# pse84_a0 register map
Vendor: Infineon Technologies; Series: PSE84_A0; File version: 1.0
CPU: CM33 r0p1, little endian, MPU, FPU, VTOR, 3 interrupt priority bits
Registers are 32-bit, read-write, reset 0x0 unless marked. A register's access mark holds for its fields unless they carry their own. Offsets are from the block's base; [hi:lo] are bit positions; lines under a group give offsets from that group; {n}, {i} and the like mark numbered series; 'fields as' and 'values as' point back to an identical list; <NAME> marks a mode.

## SRSS (part 2 of 2) — SRSS Core Registers
Base 0x42400000
0x1540 CSV_PILO_REF_SEL — Select CSV Reference clock for PILO clock
  [1:0] PILO_REF_MUX — Selects a source for clock clk_ref_pilo. Note that not all products support all clock sources. Selecting a clock source that is not supported will result in undefined behavior. It takes four cycles of the originally selected clock to switch away from it. Do not disable the original clock during this time. PILO is a source for clk_lf. Do not select LF when LF clock is using PILO.
    0=LFCLK (Root of the low-speed clock tree (LFCLK)); 1=ILO (Internal Low frequency Oscillator, available in Active, DeepSleep, and Hibernate. (Product Specific)); 2=WCO (Watch-crystal oscillator input, available in Active, DeepSleep, and Hibernate. (Product Specific)); 3=TIMERCLK (Timer clock. Divided clock from IHO set to 1MHz. Available only during Active mode. If this clock is selected as reference, CSV will be disabled by hardware when entering lower power modes (DPSLP) and re-enabled back in Active.)
{0x1600+0x20*i} CLK_DPLL_LP[{i}] (i=0..1) group — DPLL LP Configuration Register
  0x00 CONFIG reset 0x20116 — DPLL_LP Configuration Register
    [31] ENABLE — Master enable for PLL. Setup FEEDBACK_DIV, REFERENCE_DIV, and OUTPUT_DIV at least one cycle before setting ENABLE=1. fOUT = (FEEDBACK_DIV + FRAC_EN*FRAC_DIV/2^24) * (fREF / REFERENCE_DIV) / (OUTPUT_DIV) 0: Block is disabled. When the PLL disables, hardware controls the bypass mux as described in BYPASS_SEL, before disabling the PLL circuit. 1: Block is enabled
    [29:28] BYPASS_SEL — Bypass mux located just after PLL output. This selection is glitch-free and can be changed while the PLL is running. When changing BYPASS_SEL, do not turn off the reference clock or PLL clock for five cycles (whichever is slower).
      0=AUTO (Automatic using lock indicator. When unlocked, automatically selects PLL reference input (bypass mode). When locked, automatically selects PLL output. If ENABLE=0, automatically selects PLL reference input.); 1=LOCKED_OR_NOTHING (Similar to AUTO, except the clock is gated off when unlocked. This is compatible with clock supervision, because the supervisors allow no clock during startup (until a timeout occurs), and the clock targets the proper frequency whenever it is running. If ENABLE=0, no clock is output.); 2=PLL_BYPASS (Select PLL reference input (bypass mode). Ignores lock indicator); 3=PLL_OUT (Select PLL output. Ignores lock indicator. If ENABLE=0, no clock is output.)
    [27] PLL_DCO_MODE — dco_mode='0' DCO freq 160-310MHz , '1' - DCO freq 310-480MHz
    [20:16] OUTPUT_DIV — Control bits for Output divider. Set the divide value before enabling the PLL, and do not change it while PLL is enabled. 0: illegal (undefined behavior) 1: divide by 1. Suitable for direct usage as HFCLK source. 2: divide by 2. Suitable for direct usage as HFCLK source. ... 16: divide by 16. Suitable for direct usage as HFCLK source. >16: illegal (undefined behavior)
    [12:8] REFERENCE_DIV — Control bits for reference divider. Set the divide value before enabling the PLL, and do not change it while PLL is enabled. 0: illegal (undefined behavior) 1: divide by 1 ... 16: divide by 16 others: illegal (undefined behavior) When using fractional mode, the jitter specs are met over the restricted range of 1 to 4, inclusive.
    [7:0] FEEDBACK_DIV — Control bits for feedback divider. Set the divide value before enabling the PLL, and do not change it while PLL is enabled. 0-15: illegal (undefined behavior) 16: divide by 16 ... 200: divide by 200 >200: illegal (undefined behavior) When using fractional mode, the jitter specs are met over the restricted range of 27 to 47, inclusive.
  0x04 CONFIG2 — DPLL_LP Configuration Register 2
    [31] FRAC_EN — Enables fractional division mode. When using fractional division mode, see CLK_PLL400M_CONFIG.LOCK_DELAY for an additional configuration requirement.
    [30:28] FRAC_DITHER_EN
    [23:0] FRAC_DIV — Control bits for fractional divider. This value is interpreted as a fraction of the PFD frequency, i.e. fPFD * (FRAC_DIV/2^24). This field can be dynamically updated within the 1000ppm control limit. It takes up to 115 AHB cycles to transfer the setting to the PLL, and writes that occur faster may be silently ignored and require the application to write again after the previous update has finished. Reading the register returns the accepted value. The PLL will start targeting the new value, but it may take significant time (milliseconds) to stabilize at the new average value. Do not change the FRAC_DIV setting while the PLL is initially locking.
  0x08 CONFIG3 — DPLL_LP Configuration Register 3
    [31] SSCG_EN — Enables spreading mode. When using spreading, see CLK_PLL400M_CONFIG.LOCK_DELAY for an additional configuration requirement.
    [28] SSCG_MODE
    [24] SSCG_DITHER_EN
    [18:16] SSCG_RATE
    [9:0] SSCG_DEPTH
  0x0C CONFIG4 reset 0xF — DPLL_LP Configuration Register 4
    [31] DCO_SD_EN — Enable the DCO sigma-delta modulator to reduce sideband frequency spurs caused by periodicity of DCO_CODE LSB changes. Note that enabling this introduces additional jitter which may exceed the timing closure limits near the maximum frequency. 0: disable sigma-delta modulator. 1: enable sigma-delta modulator. User must ensure the frequency remains with timing closure (consult Cypress).
    [13] PLL_CS_PB2_DIS — disable internal bias
    [10:0] DCO_CODE — Initial DCO code. It is recommended to leave this at the default setting.
  0x10 CONFIG5 reset 0x709870BA — DPLL_LP Configuration Register 5
    [31:28] KP_SSCG — Gain of P/I loop filter proportional path for SSCG operation. Gain coefficient is 2^KP, eg. 0=>1, 15=>32768.
    [23:20] KP_FRACT — Gain of P/I loop filter proportional path for FRACT operation. Gain coefficient is 2^KP, eg. 0=>1, 15=>32768.
    [19:16] KP_INT — Gain of P/I loop filter integrator path for INT operation. Gain coefficient is 2^KP, eg. 0=>1, 15=>32768.
    [15:12] KI_SSCG — Gain of P/I loop filter proportional path for SSCG operation. Gain coefficient is 2^KI, eg. 0=>1, 15=>32768.
    [7:4] KI_FRACT — Gain of P/I loop filter proportional path for FRACT operation. Gain coefficient is 2^KI, eg. 0=>1, 15=>32768.
    [3:0] KI_INT — Gain of P/I loop filter integrator path for INT operation. Gain coefficient is 2^KI, eg. 0=>1, 15=>32768.
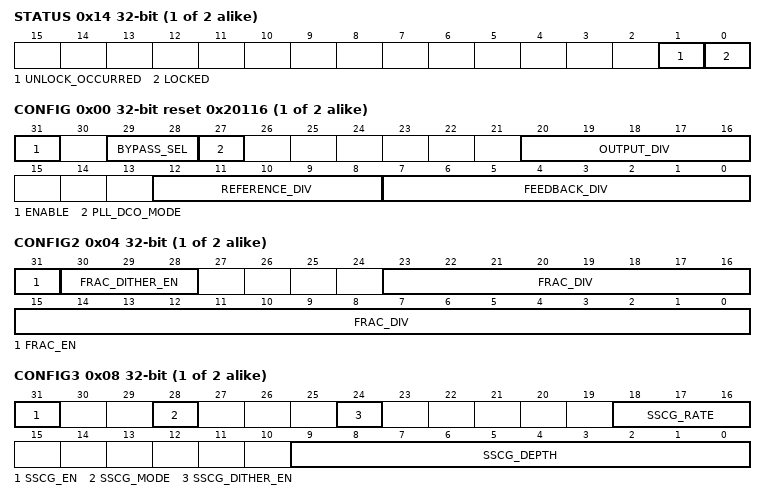
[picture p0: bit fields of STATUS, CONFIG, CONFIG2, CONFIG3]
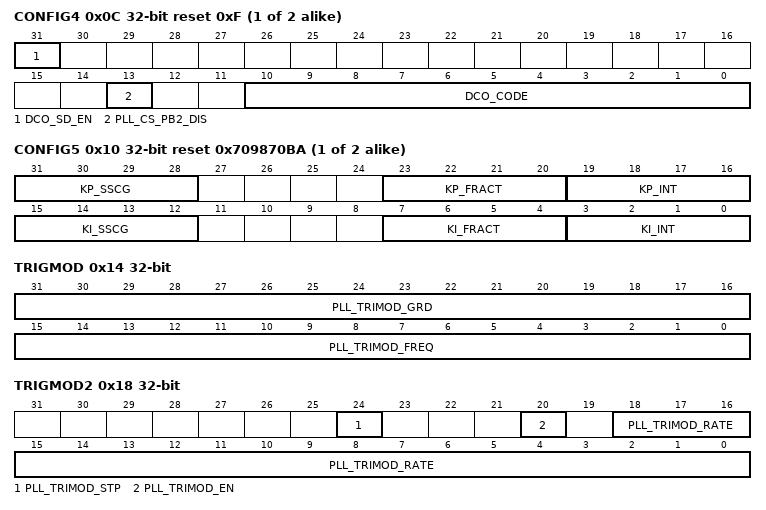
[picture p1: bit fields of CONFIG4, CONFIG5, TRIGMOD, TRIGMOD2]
  0x14 STATUS — DPLL_LP Status Register
    [1] UNLOCK_OCCURRED — This bit sets whenever the PLL Lock bit goes low, and stays set until cleared by firmware.
    [0] LOCKED ro — PLL Lock Indicator
0x1800 CLK_DPLL_HP group — DPLL HP Configuration Register
  0x00 CONFIG reset 0x1013 — DPLL_HP Configuration Register
    [31] ENABLE — Master enable for PLL. Setup PLL for integer, fract or SCSG at least one cycle before setting ENABLE=1. 0: Block is disabled. When the PLL disables, hardware controls the bypass mux as described in BYPASS_SEL, before disabling the PLL circuit. 1: Block is enabled
    [29:28] BYPASS_SEL — Bypass mux located just after PLL output. This selection is glitch-free and can be changed while the PLL is running. When changing BYPASS_SEL, do not turn off the reference clock or PLL clock for five cycles (whichever is slower).
      values as CLK_DPLL_LP[0].CONFIG.BYPASS_SEL
    [14:12] PLL_FREQ_KDIV_SEL — K-divider division factor (K = kdiv_sel_i + 1 )
    [10:8] PLL_FREQ_PDIV_SEL — P-divider division factor (P = pdiv_sel_i + 1 ) (Cannot be changed on the fly when the PLL is enabled)
    [7:0] PLL_FREQ_NDIV_INT_SEL — N-divider division factor (N = ndiv_sel_i + 1 ) (Cannot be changed on the fly when the PLL is enabled)
  0x04 CONFIG2 reset 0x8E00000 — DPLL_HP Configuration Register 2
    [27:24] PLL_IVR_TRIM — control word for trimming the regulated voltage that is internally generated from the 1v8 supply (default value = '10') (Cannot be changed on the fly when the PLL is enabled)
    [23:21] PLL_FREQ_MODE_SEL — selects the waiting time for Power Initialization sequence, based on the PLL running frequency (Cannot be changed on the fly when the PLL is enabled)
    [20:0] PLL_FREQ_NDIV_FRACT_SEL — N-divider division factor (N = ndiv_sel_i + 1) (Cannot be changed on the fly when the PLL is enabled)
  0x08 CONFIG3 reset 0x1 — DPLL_HP Configuration Register 3
    [29] PLL_FDSM_SEL — DSM clock division select (Cannot be changed on the fly when the PLL is enabled)
      0=DIV_BY_4 (Divide output by 4); 1=DIV_BY_2 (Divide output by 2)
    [0] PLL_CLKR_SEL — Select retimed reference clock (Cannot be changed on the fly when the PLL is enabled)
  0x0C CONFIG4 reset 0x27618AC — DPLL_HP Configuration Register 4
    [30:27] PLL_FLOCK_OBSWIN — Period over which PQDIFF is computed/observed. If 0 = use HW computed window. Supported values: 0-4 and 8 (Cannot be changed on the fly when the PLL is enabled)
    [26:23] PLL_FLOCK_LK_WAITPER — Period over which flock_en_thresh must be met in order for Freq Locking. Supported values: 0-8 (Cannot be changed on the fly when the PLL is enabled)
    [22:20] PLL_FLOCK_LK_THRESH — PQDIFF threshold under which DLL asserts Freq LOCK (Cannot be changed on the fly when the PLL is enabled)
    [19:16] PLL_FLOCK_WAITPER — Period over which flock_en_thresh must be met in order for FINE Filtering enabling. Supported values: 0-8 (Cannot be changed on the fly when the PLL is enabled)
    [13:11] PLL_FLOCK_EN_THRESH — PQDIFF threshold under which FINE Filtering gets enabled (Cannot be changed on the fly when the PLL is enabled) CONFIG.PLL_FREQ_NDIV_INT_SEL >= 20 -> PLL_FLOCK_EN_THRESH == 0x7; CONFIG.PLL_FREQ_NDIV_INT_SEL < 20 -> PLL_FLOCK_EN_THRESH == 0x3;
    [9:5] PLL_LF_LC_BETA — Beta value of the coarse filter (Cannot be changed on the fly when the PLL is enabled)
    [4:0] PLL_LF_LC_ALPHA — Alpha value of the coarse filter (Cannot be changed on the fly when the PLL is enabled)
  0x10 CONFIG5 reset 0x1294 — DPLL_HP Configuration Register 5
    [28:16] PLL_DT_CAL_DIG ro — FW should read pll_dutycal_dig_o only when pll_dutycal_ok is high to know the status of DUTY CAL circuit.
    [12] PLL_LF_SET_PARAMS — enable for external loop filter control (alpha and beta values) (Cannot be changed on the fly when the PLL is enabled)
    [9:5] PLL_LF_BETA — External beta value (Cannot be changed on the fly when the PLL is enabled) Fref/(pdiv_sel_i+1) >= 25MHz -> PLL_LF_BETA == 0x14 Fref/(pdiv_sel_i+1) < 25MHz -> PLL_LF_BETA == 0x10
    [4:0] PLL_LF_ALPHA — External alpha value (Cannot be changed on the fly when the PLL is enabled)
  0x14 TRIGMOD — DPLL_HP Trigmod SSCG Register
    [31:16] PLL_TRIMOD_GRD — Triangular-Frequency Modulation: modulation gradient. See formula in the BROS (word file) (Can be changed when PLL is enabled but cannot be changed on the fly when pll_trimod_en_i=1)
    [15:0] PLL_TRIMOD_FREQ — Triangular-Frequency Modulation: modulation frequency. See formula in the BROS (word file) (Can be changed when PLL is enabled but cannot be changed on the fly when pll_trimod_en_i=1)
  0x18 TRIGMOD2 — DPLL_HP Trigmod2 SSCG Register
    [24] PLL_TRIMOD_STP — Triangular-Frequency Modulation stop
    [20] PLL_TRIMOD_EN — Triangular-Frequency Modulation enable
    [18:0] PLL_TRIMOD_RATE — triangular frequency modulation: trimod_rate = mod_grad_i * 16/mod_freq_i (Cannot be changed on the fly when the PLL is enabled)
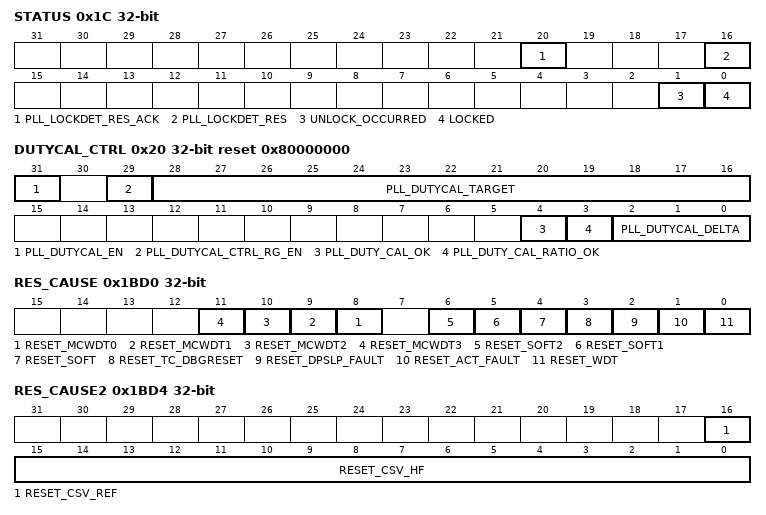
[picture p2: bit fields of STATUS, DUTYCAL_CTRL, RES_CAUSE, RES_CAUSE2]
  0x1C STATUS — DPLL_HP Status Register
    [20] PLL_LOCKDET_RES_ACK ro — acknowledgement for lock detection restart
    [16] PLL_LOCKDET_RES — Restart lock detector
    [1] UNLOCK_OCCURRED — This bit sets whenever the PLL Lock bit goes low, and stays set until cleared by firmware.
    [0] LOCKED ro — PLL Lock Indicator
  0x20 DUTYCAL_CTRL reset 0x80000000 — DPLL_HP_User DUTYCAL Control Register
    [31] PLL_DUTYCAL_EN — dutycal: enables duty cycle calibration (Cannot be changed on the fly when the PLL is enabled)
    [29] PLL_DUTYCAL_CTRL_RG_EN — dutycal: enables ring oscillator for duty cycle digitization (Cannot be changed on the fly when the PLL is enabled)
    [28:16] PLL_DUTYCAL_TARGET — duty cycle target (Cannot be changed on the fly when the PLL is enabled)
    [4] PLL_DUTY_CAL_OK ro — Status of the duty calibration ok
    [3] PLL_DUTY_CAL_RATIO_OK ro — Status of the duty calibration ratio ok
    [2:0] PLL_DUTYCAL_DELTA — dutycal: margins for the duty cycle calibration error (Cannot be changed on the fly when the PLL is enabled)
0x1BD0 RES_CAUSE — Reset Cause Observation Register
  [n+8] RESET_MCWDT{n} (n=0..3) — Multi-Counter Watchdog timer reset #{n}. This is a low-voltage cause bit that hardware clears when the low-voltage supply is initialized (see comments above).
  [6] RESET_SOFT2 — CPU[2] requested a system reset through it's SYSRESETREQ. This can be done via a debugger probe or in firmware. This is a low-voltage cause bit that hardware clears when the low-voltage supply is initialized (see comments above).
  [5] RESET_SOFT1 — CPU[1] requested a system reset through it's SYSRESETREQ. This can be done via a debugger probe or in firmware. This is a low-voltage cause bit that hardware clears when the low-voltage supply is initialized (see comments above).
  [4] RESET_SOFT — CPU[0] requested a system reset through it's SYSRESETREQ. This can be done via a debugger probe or in firmware. This is a low-voltage cause bit that hardware clears when the low-voltage supply is initialized (see comments above).
  [3] RESET_TC_DBGRESET — Test controller or debugger asserted reset. This asserts low-voltage resets including the debug domain. This is a low-voltage cause bit that hardware clears when the low-voltage supply is initialized (see comments above).
  [2] RESET_DPSLP_FAULT
  [1] RESET_ACT_FAULT — Fault logging system requested a reset from its Active logic. This is a low-voltage cause bit that hardware clears when the low-voltage supply is initialized (see comments above).
  [0] RESET_WDT — A basic WatchDog Timer (WDT) reset has occurred since last power cycle. ULP products: This is a low-voltage cause bit that hardware clears when the low-voltage supply is initialized (see comments above). For products that support high-voltage cause detection, this bit blocks recording of other high-voltage cause bits, except RESET_PORVDDD, or *XRES. Hardware clears this bit during POR. This bit is not blocked by other HV cause bits.
0x1BD4 RES_CAUSE2 — Reset Cause Observation Register 2
  [16] RESET_CSV_REF — Clock supervision logic requested a reset due to loss or frequency violation of the reference clock source that is used to monitor the other HF clock sources.
  [15:0] RESET_CSV_HF — Clock supervision logic requested a reset due to loss or frequency violation of a high-frequency clock. Each bit index K corresponds to a HFCLK<K>. Unimplemented clock bits return zero.
0x1BE4 RES_PXRES_CTL wo — Programmable XRES Control Register
  [0] PXRES_TRIGGER — Triggers PXRES. This causes a full-scope reset and reboot.
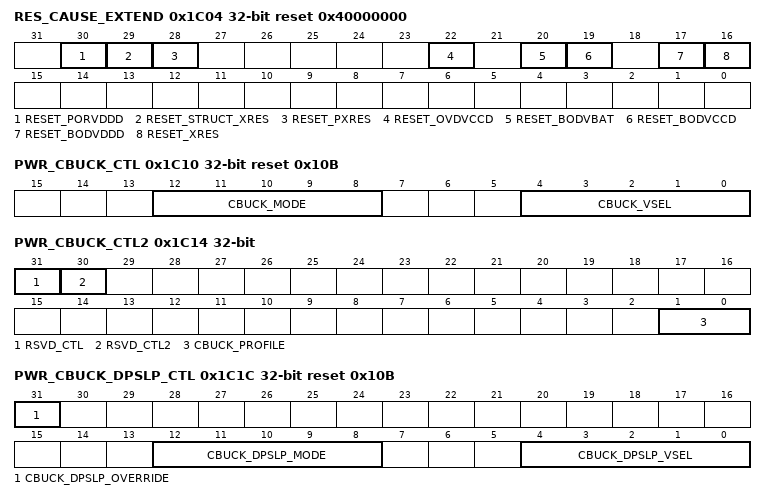
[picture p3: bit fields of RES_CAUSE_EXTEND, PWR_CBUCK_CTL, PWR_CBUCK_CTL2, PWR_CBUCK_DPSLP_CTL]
0x1C04 RES_CAUSE_EXTEND reset 0x40000000 — Extended Reset Cause Observation Register
  [30] RESET_PORVDDD — Indicator that a POR occurred. This is a high-voltage cause bit, and hardware clears the other bits when this one is set. It does not block further recording of other high-voltage causes.
  [29] RESET_STRUCT_XRES — Structural reset was asserted. This is a high-voltage cause bit that blocks recording of other high-voltage cause bits, except RESET_PORVDDD, *XRES, or WDT. Hardware clears this bit during POR. This bit is not blocked by other HV cause bits.
  [28] RESET_PXRES — PXRES triggered. This is a high-voltage cause bit that blocks recording of other high-voltage cause bits, except RESET_PORVDDD, *XRES, or WDT. Hardware clears this bit during POR. This bit is not blocked by other HV cause bits.
  [22] RESET_OVDVCCD — Overvoltage detection on the internal core VCCD supply. This is a high-voltage cause bit that blocks recording of other high-voltage cause bits, except RESET_PORVDDD, *XRES, or WDT. Hardware clears this bit during POR.
  [20] RESET_BODVBAT — External VBAT supply crossed brown-out limit. Note that this cause will only be observable as long as the VDDD supply does not go below the POR (power on reset) detection limit. Below this limit it is not possible to reliably retain information in the device. This is a high-voltage cause bit that blocks recording of other high-voltage cause bits, except RESET_PORVDDD, *XRES, or WDT. Hardware clears this bit during POR.
  [19] RESET_BODVCCD — Internal VCCD core supply crossed the brown-out limit. Note that this detector will detect gross issues with the internal core supply, but may not catch all brown-out conditions. Functional and timing supervision (CSV, WDT) is provided to create fully failsafe internal crash detection. This is a high-voltage cause bit that blocks recording of other high-voltage cause bits, except RESET_PORVDDD, *XRES, or WDT. Hardware clears this bit during POR.
  [17] RESET_BODVDDD — External VDDD supply crossed brown-out limit. Note that this cause will only be observable as long as the VDDD supply does not go below the POR (power on reset) detection limit. Below this limit it is not possible to reliably retain information in the device. This is a high-voltage cause bit that blocks recording of other high-voltage cause bits, except RESET_PORVDDD, *XRES, or WDT. Hardware clears this bit during POR.
  [16] RESET_XRES — External XRES pin was asserted. This is a high-voltage cause bit that blocks recording of other high-voltage cause bits, except RESET_PORVDDD, or WDT. Hardware clears this bit during POR. This bit is not blocked by other HV cause bits.
0x1C10 PWR_CBUCK_CTL reset 0x10B — Core Buck Control Register
  [12:8] CBUCK_MODE — CBUCK mode. Low ripple (high power) modes are intended for analog that needs low ripple. Low power mode is suitable for digital processing. The CBUCK mode is defined as = {mode*_sr_mode, mode*_sr_hp_submode[1:0], mode*_sr_lp_submode[1:0]} The actual CBUCK mode is the maximum of this setting and the settings of all enabled step-down regulators. 0x11: HP,Hysteretic PFM, High-Low (default Active) 0x01: LP,Hysteretic PFM, High-Low (default DeepSleep)
  [4:0] CBUCK_VSEL — Voltage output selection. This register is only reset by XRES, HIBERNATE wakeup, or supply supervision reset. The actual CBUCK voltage is the maximum of this setting and the settings for selected mode (see PWR_BUCK_CTL.MODE). These settings follow the formula (0.58+0.02*CBUCK_VSEL). 0: 0.58V, 1: 0.60V, 2: 0.62V, 3: 0.64V, 4: 0.66V, 5: 0.68V, 6: 0.70V, 7: 0.72V, 8: 0.74V, 9: 0.76V, 10: 0.78V, 11: 0.80V, 12: 0.82V, 13: 0.84V, 14: 0.86V, 15: 0.88V, 16: 0.90V, 17: 0.92V, 18: 0.94V, 19: 0.96V, 20: 0.98V, 21: 1.00V, 22: 1.02V, 23: 1.04V, 24: 1.06V, 25: 1.08V, 26: 1.10V, 27: 1.12V, 28: 1.14V, 29: 1.16V, 30: 1.18V, 31: 1.20V.
0x1C14 PWR_CBUCK_CTL2 — Core Buck Control Register 2
  [31] RSVD_CTL
  [30] RSVD_CTL2
  [1:0] CBUCK_PROFILE — Selects between CBUCK mode profiles. When CBUCK_USE_SETTING=1, PWR_CBUCK_CTL settings are included in the harmonization and the maximum of the respective mode is used. 00: Mode0: VSEL=0.8V; MODE= HP,Hysteretic PFM, High-Low (17) 01: Mode1: VSEL=0.7V; MODE=17 10: Mode2: VSEL=0.9V; MODE=17 11: Forces the CBUCK to use the settings in PWR_CBUCK_CTL register, ignoring the other hardware requests. This can be used as part of a firmware algorithm to change the voltage of an regulator. This bit is cleared by any reset].
0x1C1C PWR_CBUCK_DPSLP_CTL reset 0x10B — Core Buck Deepsleep Control Register
  [31] CBUCK_DPSLP_OVERRIDE — Causes the settings in CBUCK_DPSLP_VSEL and CBUCK_DPSLP_MODE in this register to be used during DEEPSLEEP. Can be used to override the normal hardware voltage behavior of 0.7V and LP, LP,Hysteretic PFM, High-Low (default DeepSleep)
  [12:8] CBUCK_DPSLP_MODE — CBUCK mode. Low ripple (high power) modes are intended for analog that needs low ripple. Low power mode is suitable for digital processing. The CBUCK mode is defined as = {mode*_sr_mode, mode*_sr_hp_submode[1:0], mode*_sr_lp_submode[1:0]} CBUCK_DPSLP_OVERRIDE=1 will casue these settings to be used during DEEPSLEEP mode. 0x11: HP,Hysteretic PFM, High-Low (default Active) 0x01: LP,Hysteretic PFM, High-Low (default DeepSleep)
  [4:0] CBUCK_DPSLP_VSEL — Voltage output selection for DEEPSLEEP. CBUCK_DPSLP_OVERRIDE=1 will casue these settings to be used during DEEPSLEEP mode. This register is only reset by XRES, HIBERNATE wakeup, or supply supervision reset. These settings follow the formula (0.58+0.02*CBUCK_VSEL). 0: 0.58V, 1: 0.60V, 2: 0.62V, 3: 0.64V, 4: 0.66V, 5: 0.68V, 6: 0.70V, 7: 0.72V, 8: 0.74V, 9: 0.76V, 10: 0.78V, 11: 0.80V, 12: 0.82V, 13: 0.84V, 14: 0.86V, 15: 0.88V, 16: 0.90V, 17: 0.92V, 18: 0.94V, 19: 0.96V, 20: 0.98V, 21: 1.00V, 22: 1.02V, 23: 1.04V, 24: 1.06V, 25: 1.08V, 26: 1.10V, 27: 1.12V, 28: 1.14V, 29: 1.16V, 30: 1.18V, 31: 1.20V.
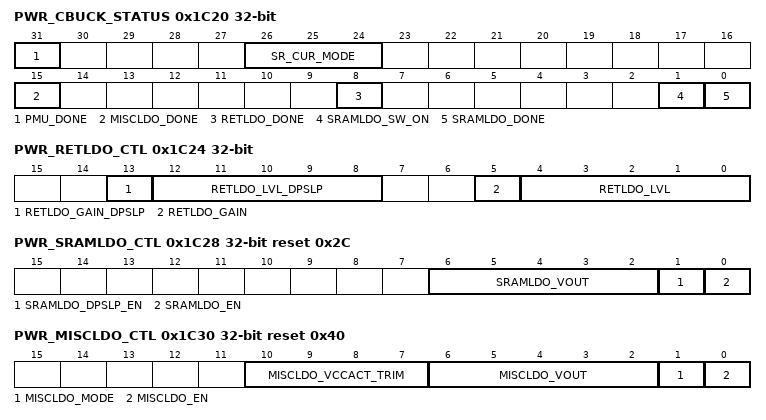
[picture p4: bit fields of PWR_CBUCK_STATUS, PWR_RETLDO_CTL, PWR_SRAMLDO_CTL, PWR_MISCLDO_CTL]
0x1C20 PWR_CBUCK_STATUS ro — Core Buck Status Register
  [31] PMU_DONE — Indicates the power management unit is finished with a transition. 0: PMU busy 1: PMU done
  [26:24] SR_CUR_MODE — Indicates the switching regulator current operating mode
  [15] MISCLDO_DONE — Indicates the MISCLDO is finished with a transition. 0: MISCLDO busy 1: MISCLDO done
  [8] RETLDO_DONE — Indicates the RETLDO is finished with a transition. 0: RETLDO busy 1: RETLDO done
  [1] SRAMLDO_SW_ON — Indicates the state of the SRAMLDO bypass switch 0: SRAMLDO enabled 1: SRAMLDO bypassed
  [0] SRAMLDO_DONE — Indicates the SRAMLDO is finished with a transition. 0: SRAMLDO busy 1: SRAMLDO done
0x1C24 PWR_RETLDO_CTL — RETLDO Control Register
  [13] RETLDO_GAIN_DPSLP — RETLDO Gain during Deepslp modes 0: 2.00 1: 2.47
  [12:8] RETLDO_LVL_DPSLP — RETLDO output voltage during DEEPSLEEP modes retldo_gain=0 retldo_gain=1 retref_lvl Temp Temp 25C-125C Temp Temp 25C-125C <4:0> -40C -40C 00000 0.6150 0.550 0.7595 0.679 00001 0.6262 0.560 0.7733 0.691 00010 0.6374 0.570 0.7871 0.704 00011 0.6485 0.580 0.8010 0.716 00100 0.6597 0.590 0.8148 0.728 00101 0.6709 0.600 0.8286 0.741 00110 0.6821 0.610 0.8424 0.753 00111 0.6933 0.620 0.8562 0.765 01000 0.7045 0.630 0.8700 0.778 01001 0.7045 0.630 0.8700 0.778 01010 0.7045 0.630 0.8700 0.778 01011 0.7045 0.630 0.8700 0.778 01100 0.7045 0.630 0.8700 0.778 01101 0.7045 0.630 0.8700 0.778 01110 0.7045 0.630 0.8700 0.778 01111 0.7045 0.630 0.8700 0.778 10000 0.4361 0.390 0.5386 0.481 10001 0.4473 0.400 0.5524 0.494 10010 0.4585 0.410 0.5662 0.506 10011 0.4696 0.420 0.5800 0.519 10100 0.4808 0.430 0.5938 0.531 10101 0.4920 0.440 0.6076 0.543 10110 0.5032 0.450 0.6214 0.556 10111 0.5144 0.460 0.6352 0.568 11000 0.5255 0.470 0.6490 0.580 11001 0.5367 0.480 0.6629 0.593 11010 0.5479 0.490 0.6767 0.605 11011 0.5591 0.500 0.6905 0.617 11100 0.5703 0.510 0.7043 0.630 11101 0.5815 0.520 0.7181 0.642 11110 0.5926 0.530 0.7319 0.654 11111 0.6038 0.540 0.7457 0.667
  [5] RETLDO_GAIN — RETLDO Gain During Active mode 0: 2.00 1: 2.47
  [4:0] RETLDO_LVL — RETLDO output voltage during DEEPSLEEP modes retldo_gain=0 retldo_gain=1 retref_lvl Temp Temp 25C-125C Temp Temp 25C-125C <4:0> -40C -40C 00000 0.6150 0.550 0.7595 0.679 00001 0.6262 0.560 0.7733 0.691 00010 0.6374 0.570 0.7871 0.704 00011 0.6485 0.580 0.8010 0.716 00100 0.6597 0.590 0.8148 0.728 00101 0.6709 0.600 0.8286 0.741 00110 0.6821 0.610 0.8424 0.753 00111 0.6933 0.620 0.8562 0.765 01000 0.7045 0.630 0.8700 0.778 01001 0.7045 0.630 0.8700 0.778 01010 0.7045 0.630 0.8700 0.778 01011 0.7045 0.630 0.8700 0.778 01100 0.7045 0.630 0.8700 0.778 01101 0.7045 0.630 0.8700 0.778 01110 0.7045 0.630 0.8700 0.778 01111 0.7045 0.630 0.8700 0.778 10000 0.4361 0.390 0.5386 0.481 10001 0.4473 0.400 0.5524 0.494 10010 0.4585 0.410 0.5662 0.506 10011 0.4696 0.420 0.5800 0.519 10100 0.4808 0.430 0.5938 0.531 10101 0.4920 0.440 0.6076 0.543 10110 0.5032 0.450 0.6214 0.556 10111 0.5144 0.460 0.6352 0.568 11000 0.5255 0.470 0.6490 0.580 11001 0.5367 0.480 0.6629 0.593 11010 0.5479 0.490 0.6767 0.605 11011 0.5591 0.500 0.6905 0.617 11100 0.5703 0.510 0.7043 0.630 11101 0.5815 0.520 0.7181 0.642 11110 0.5926 0.530 0.7319 0.654 11111 0.6038 0.540 0.7457 0.667
0x1C28 PWR_SRAMLDO_CTL reset 0x2C — SRAMLDO Control Register
  [6:2] SRAMLDO_VOUT — SRAMLDO output voltage Setting Voltage(V) Setting Voltage(V) 00000 0.58 10000 0.90 00001 0.60 10001 0.92 00001 0.60 10001 0.92 00010 0.62 10010 0.94 00011 0.64 10011 0.96 00100 0.66 10100 0.98 00101 0.68 10101 1.00 00110 0.70 10110 1.02 00111 0.72 10111 1.04 01000 0.74 11000 1.06 01001 0.76 11001 1.08 01010 0.78 11010 1.10 01011 0.80 11011 1.12 01100 0.82 11100 1.14 01101 0.84 11101 1.16 01110 0.86 11110 1.18 01111 0.88 11111 1.20
  [1] SRAMLDO_DPSLP_EN — Enable SRAMLDO during deepsleep modes for fast wakeup time versus power savings.
  [0] SRAMLDO_EN — SRAM LDO enable 0: Disabled (switch VCCD->VCCSRAM enabled) 1: Enabled (switch VCCD->VCCSRAM disabled)
0x1C30 PWR_MISCLDO_CTL reset 0x40 — MISCLDO Control Register
  [10:7] MISCLDO_VCCACT_TRIM — MISCLDO VCCACT_MISC trim adjustment. Proportional to VCCACT_MISC, numbers below at 0.9V. Setting Adj @0.9V 0111 35mV 0110 30mV 0101 25mV 0100 20mV 0011 15mV 0010 10mV 0001 5mV 0000 0mV 1111 -5mV 1110 -10mV 1110 -10mV 1101 -15mV 1100 -20mV 1011 -25mV 1010 -30mV 1001 -35mV 1000 -40mV
  [6:2] MISCLDO_VOUT — MISCLDO output voltage Setting Voltage(V) Setting Voltage(V) 00000 0.58 10000 0.90 00001 0.60 10001 0.92 00010 0.62 10010 0.94 00011 0.64 10011 0.96 00100 0.66 10100 0.98 00101 0.68 10101 1.00 00110 0.70 10110 1.02 00111 0.72 10111 1.04 01000 0.74 11000 1.06 01001 0.76 11001 1.08 01010 0.78 11010 1.10 01011 0.80 11011 1.12 01100 0.82 11100 1.14 01101 0.84 11101 1.16 01110 0.86 11110 1.18 01111 0.88 11111 1.20
  [1] MISCLDO_MODE — MISCLDO voltage mode 0: MISCLDO output follows VCCACT_MISC 1: MISCLDO output follows miscldo_vout<4:0>
  [0] MISCLDO_EN — MISCLDO enable
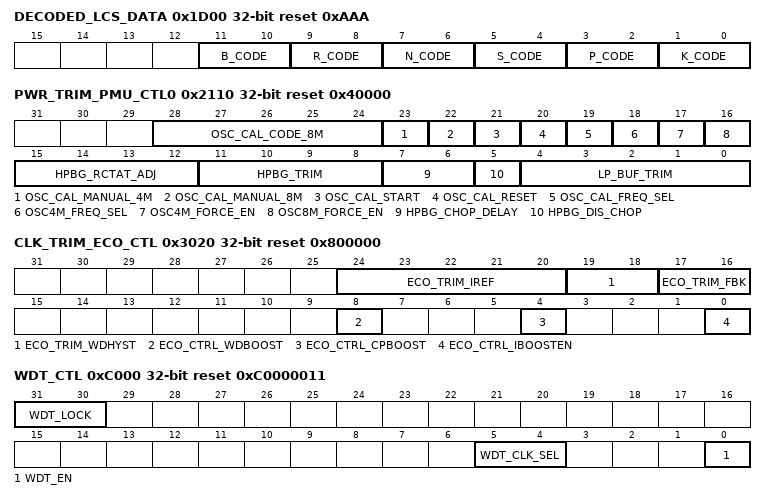
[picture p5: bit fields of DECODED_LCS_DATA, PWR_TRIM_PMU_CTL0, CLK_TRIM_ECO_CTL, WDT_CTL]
0x1D00 DECODED_LCS_DATA ro reset 0xAAA — Decoded Life Cycle Stage Data Register
  [11:10] B_CODE — Indicates status of LCS 'B' bit. 00=Unprogrammed, 11=Valid, 10/01=Invalid
  [9:8] R_CODE — Indicates status of LCS 'R' bit. 00=Unprogrammed, 11=Valid, 10/01=Invalid
  [7:6] N_CODE — Indicates status of LCS 'N' bit*. 00=Unprogrammed, 11=Valid, 10/01=Invalid. Will be '00' if R_CODE is set in RMA LCS
  [5:4] S_CODE — Indicates status of LCS 'S' bit*. 00=Unprogrammed, 11=Valid, 10/01=Invalid. Will be '11' if R_CODE is set in RMA LCS
  [3:2] P_CODE — Indicates status of LCS 'P' bit*. 00=Unprogrammed, 11=Valid, 10/01=Invalid. Will be '11' if R_CODE is set in RMA LCS
  [1:0] K_CODE — Indicates status of LCS 'K' bit. 00=Unprogrammed, 11=Valid, 10/01=Invalid
0x2110 PWR_TRIM_PMU_CTL0 reset 0x40000 — PMU Trim Register 0
  [28:24] OSC_CAL_CODE_8M — Manual trim code to apply to 8MHz oscillator. Only used if osc_cal_manual_8M=1.
  [23] OSC_CAL_MANUAL_4M — Set to use manual cal code for 3.2/4MHz oscillator 0 Use calibration result 1 Use osc_cal_code_4M<4:0>
  [22] OSC_CAL_MANUAL_8M — Set to use manual cal code for 8MHz oscillator 0 Use calibration result 1 Use osc_cal_code_8M<4:0>
  [21] OSC_CAL_START — Start oscillator calibration
  [20] OSC_CAL_RESET — Reset osc cal codes and cal_done signal
  [19] OSC_CAL_FREQ_SEL — Select oscillator to calibrate 0: 8MHz 1: 3.2M/4MHz
  [18] OSC4M_FREQ_SEL — PWM oscillator frequency select 0: 4.0MHz 1 : 3.2MHz
  [17] OSC4M_FORCE_EN — 3.2/4MHz (PWM) oscillator enable - use for Calibration 0: Auto (powerup when used) 1: Enabled (3.2/4MHz always on)
  [16] OSC8M_FORCE_EN — 8MHz oscillator enable - use for Calibration 0: Auto (powerup when used) 1: Enabled (8MHz always on)
  [15:12] HPBG_RCTAT_ADJ — High power bandgap adjust for 0TC (TTTT,50C)
  [11:8] HPBG_TRIM — High power bandgap reference voltage trim Setting VOUT @1.16V VOUT percent 0111 41mV +3.4 percent 0110 35mV +2.9 percent 0101 29mV +2.4 percent 0100 23mV +1.9 percent 0011 18mV +1.5 percent 0010 12mV +1.0 percent 0001 6mV +0.5 percent 0000 0mV 0.0 percent 1111 -5mV -0.4 percent 1110 -11mV -1.0 percent 1101 -16mV -1.4 percent 1100 -22mV -1.9 percent 1011 -27mV -2.4 percent 1010 -32mV -2.8 percent 1001 -38mV -3.4 percent 1000 -43mV -3.9 percent
  [7:6] HPBG_CHOP_DELAY — HPBG chopping delay Setting Delay 00 16us 01 32us 10 64us 11 128us
  [5] HPBG_DIS_CHOP — HPBG disable chop
  [4:0] LP_BUF_TRIM — LP buffer voltage trim, 2's compliment format Setting Vref(V) Setting Vref(V) 00000 0.600 10000 0.520 (-13.3 percent) 00001 0.605 (+0.83 percent) 10001 0.525 (-12.5 percent) 00010 0.610 (+1.67 percent) 10010 0.530 (-11.7 percent) 00011 0.615 (+2.50 percent) 10011 0.535 (-10.8 percent) 00100 0.620 (+3.33 percent) 10100 0.540 (-10.0 percent) 00101 0.625 (+4.17 percent) 10101 0.545 (-9.17 percent) 00110 0.630 (+5.00 percent) 10110 0.550 (-8.33 percent) 00111 0.635 (+5.83 percent) 10111 0.555 (-7.50 percent) 01000 0.640 (+6.67 percent) 11000 0.560 (-6.67 percent) 01001 0.645 (+7.50 percent) 11001 0.565 (-5.83 percent) 01010 0.650 (+8.33 percent) 11010 0.570 (-5.00 percent) 01011 0.655 (+9.17 percent) 11011 0.575 (-4.17 percent) 01100 0.660 (+10.0 percent) 11100 0.580 (-3.33 percent) 01101 0.665 (+10.8 percent) 11101 0.585 (-2.50 percent) 01110 0.670 (+11.7 percent) 11110 0.590 (-1.67 percent) 01111 0.675 (+12.5 percent) 11111 0.595 (-0.83 percent)
0x3020 CLK_TRIM_ECO_CTL reset 0x800000 — ECO Trim Register
  [24:20] ECO_TRIM_IREF — Current bias trim input pin
  [19:18] ECO_TRIM_WDHYST — Watchdog hysteresis trim
  [17:16] ECO_TRIM_FBK — Feedback resistance trim
  [8] ECO_CTRL_WDBOOST — Watchdog trim
  [4] ECO_CTRL_CPBOOST — Amplitude trim
  [0] ECO_CTRL_IBOOSTEN — Current boost enable input pin
0x4000 RAM_TRIM group — SRAM Trim registers
  {0x0+4j} TRIM_RAM_CTL[{j}] (j=0..9) — Trim Register for RAM Type 0
    [31:0] TRIM — Trim value for RAM Type 0
0xC000 WDT_CTL reset 0xC0000011 — Watchdog Counter Control Register (Type A)
  [31:30] WDT_LOCK — Prohibits writing to WDT_*, CLK_ILO_CONFIG, CLK_SELECT.LFCLK_SEL, and CLK_TRIM_ILO_CTL registers when not equal 0. Requires at least two different writes to unlock. A change in WDT_LOCK takes effect beginning with the next write cycle. Note that this field is 2 bits to force multiple writes only. It represents only a single write protect signal protecting all those registers at the same time. WDT will lock on any reset. This field is not retained during DEEPSLEEP or HIBERNATE mode, so the WDT will be locked after wakeup from these modes.
    0=NO_CHG (No effect); 1=CLR0 (Clears bit 0); 2=CLR1 (Clears bit 1); 3=SET01 (Sets both bits 0 and 1)
  [5:4] WDT_CLK_SEL — Select source for WDT. Not all products support all clock sources. Selecting a clock source that is not supported will result in undefined behavior. Writes to this field are ignored unless the WDT is unlock using WDT_LOCK register. It takes four cycles of the originally selected clock to switch away from it. Do not disable the original clock during this time.
    0=ILO (ILO - Internal Low-speed Oscillator, if present. With this option selected, ILO reset is suppressed in Hibernate mode.); 1=PILO (PILO - Precision ILO. If present. With this option selected, PILO reset is suppressed in Hibernate mode.); 2=RTC (RTC - Selected clk_rtc source, if present. This choice is not recommended for applications that rely upon the watchdog timer for safety or security, unless the product supports clock supervision of clk_rtc (CSV_RTC). Generation of clk_rtc is not protected by WDT_LOCK and is in a different memory region with potentially different security attributes.)
  [0] WDT_EN — Enable this watchdog timer. This field is retained during DEEPSLEEP and HIBERNATE modes.
0xC004 WDT_CNT — Watchdog Counter Count Register (Type A)
  [31:0] COUNTER — Current value of WDT Counter. The write feature of this register is for verification purpose, have no synchronization, and can only be applied when the WDT is fully off. When writing, the value is updated immediately in the WDT counter, but it will read back as the old value until this register resynchronizes just after the negedge of selected WDT clock. Writes will be ignored if they occur when the WDT is enabled.
0xC008 WDT_MATCH reset 0x1000 — Watchdog Counter Match Register (Type A)
  [31:0] MATCH — Match value for Watchdog counter. Every time WDT_COUNTER reaches MATCH an interrupt is generated. Two unserviced interrupts will lead to a system reset (i.e. at the third match).
0xC00C WDT_MATCH2 reset 0x1F — Watchdog Counter Match Register 2 (Type A)
  [4:0] IGNORE_BITS_ABOVE — The number of bits to be considered for matching starting from LSb of the register. Bit indices above this setting are NOT checked against MATCH. This value provides control over the time-to-reset of the watchdog (which happens after 3 successive matches). The four LSBs cannot be ignored for matching. Settings <3 behave like a setting of 3. If the setting is higher than the number of bits in the WDT counter, all actual bits in the counter are matched.
{0xD000+0x40*i} MCWDT_STRUCT[{i}] (i=0..1) group — Multi-Counter Watchdog Timer (Type A)
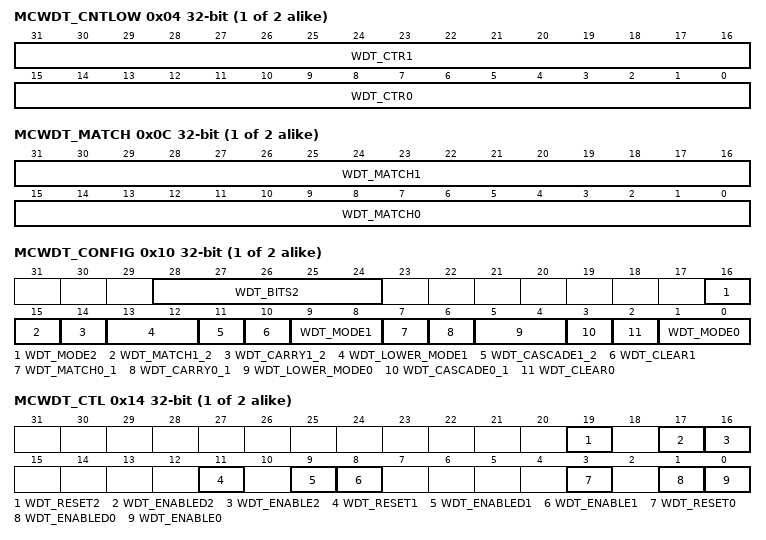
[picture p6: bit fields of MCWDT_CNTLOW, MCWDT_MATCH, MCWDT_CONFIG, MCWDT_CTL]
  0x04 MCWDT_CNTLOW — Multi-Counter Watchdog Sub-counters 0/1
    [31:16] WDT_CTR1 — Current value of sub-counter 1 for this MCWDT. Software writes are ignored when the sub-counter is enabled
    [15:0] WDT_CTR0 — Current value of sub-counter 0 for this MCWDT. Software writes are ignored when the sub-counter is enabled.
  0x08 MCWDT_CNTHIGH — Multi-Counter Watchdog Sub-counter 2
    [31:0] WDT_CTR2 — Current value of sub-counter 2 for this MCWDT. Software writes are ignored when the sub-counter is enabled
  0x0C MCWDT_MATCH — Multi-Counter Watchdog Counter Match Register
    [31:16] WDT_MATCH1 — Match value for sub-counter 1 of this MCWDT
    [15:0] WDT_MATCH0 — Match value for sub-counter 0 of this MCWDT
  0x10 MCWDT_CONFIG — Multi-Counter Watchdog Counter Configuration
    [28:24] WDT_BITS2 — Bit to observe for WDT_INT2: 0: Assert after bit0 of WDT_CTR2 toggles (one int every tick) ... 31: Assert after bit31 of WDT_CTR2 toggles (one int every 2^31 ticks)
    [16] WDT_MODE2 — Watchdog Counter 2 Mode.
      0=NOTHING (Free running counter with no interrupt requests); 1=INT (Free running counter with interrupt request that occurs one LFCLK cycle after the specified bit in CTR2 toggles (see WDT_BITS2).)
    [15] WDT_MATCH1_2 — Specifies matching behavior when WDT_CASCADE1_2==1. When WDT_CASCADE1_2==0, this bit is not used and match is based on counter 2 alone. 0: Match based on counter 2 alone. 1: Match based on counter 2 and counter 1 matching simultaneously.
    [14] WDT_CARRY1_2 — Carry out behavior that applies when WDT_CASCADE1_2==1. This bit is not used when WDT_CASCADE1_2==0. 0: carry out on counter 1 match. 1: carry out on counter 1 roll-over.
    [13:12] WDT_LOWER_MODE1 — Watchdog Counter Action on service before lower limit.
      0=NOTHING (Do nothing); 1=INT (Assert WDT_INTx); 2=RESET (Assert WDT Reset)
    [11] WDT_CASCADE1_2 — Cascade Watchdog Counters 1,2. Counter 2 increments the cycle after WDT_CTR1=WDT_MATCH1. It is allowed to cascade all three WDT counters. 0: Independent counters 1: Cascaded counters. When cascading all three counters, WDT_CLEAR1 must be 1.
    [10] WDT_CLEAR1 — Clear Watchdog Counter when WDT_CTR1==WDT_MATCH1. In other words WDT_CTR1 divides LFCLK by (WDT_MATCH1+1). 0: Free running counter 1: Clear on match. In this mode, the minimum legal setting of WDT_MATCH1 is 1.
    [9:8] WDT_MODE1 — Watchdog Counter Action on Match. Action is taken on the next increment after the values match (WDT_CTR1=WDT_MATCH1).
      0=NOTHING (Do nothing); 1=INT (Assert WDT_INTx); 2=RESET (Assert WDT Reset); 3=INT_THEN_RESET (Assert WDT_INTx, assert WDT Reset after 3rd unhandled interrupt)
    [7] WDT_MATCH0_1 — Specifies matching behavior when WDT_CASCADE0_1==1. When WDT_CASCADE0_1==0, this bit is not used and match is based on counter 1 alone. 0: Match based on counter 1 alone. 1: Match based on counter 1 and counter 0 matching simultaneously.
    [6] WDT_CARRY0_1 — Carry out behavior that applies when WDT_CASCADE0_1==1. This bit is not used when WDT_CASCADE0_1==0. 0: carry out on counter 0 match. 1: carry out on counter 0 roll-over.
    [5:4] WDT_LOWER_MODE0 — Watchdog Counter Action on service before lower limit.
      values as WDT_LOWER_MODE1
    [3] WDT_CASCADE0_1 — Cascade Watchdog Counters 0,1. Counter 1 increments the cycle after WDT_CTR0=WDT_MATCH0. 0: Independent counters 1: Cascaded counters
    [2] WDT_CLEAR0 — Clear Watchdog Counter when WDT_CTR0=WDT_MATCH0. In other words WDT_CTR0 divides LFCLK by (WDT_MATCH0+1). 0: Free running counter 1: Clear on match. In this mode, the minimum legal setting of WDT_MATCH0 is 1.
    [1:0] WDT_MODE0 — Watchdog Counter Action on Match. Action is taken on the next increment after the values match (WDT_CTR0=WDT_MATCH0).
      values as WDT_MODE1
  0x14 MCWDT_CTL — Multi-Counter Watchdog Counter Control
    [19] WDT_RESET2 — Resets counter 2 back to 0000. Hardware will reset this bit after counter was reset. This will take up to one LFCLK cycle to take effect.
    [17] WDT_ENABLED2 ro — Indicates actual state of counter. May lag WDT_ENABLE2 by up to two LFCLK cycles.
    [16] WDT_ENABLE2 — Enable subcounter 2. May take up to 2 LFCLK cycles to take effect. 0: Counter is disabled (not clocked) 1: Counter is enabled (counting up)
    [11] WDT_RESET1 — Resets counter 1 back to 0000. Hardware will reset this bit after counter was reset. This will take up to one LFCLK cycle to take effect.
    [9] WDT_ENABLED1 ro — Indicates actual state of counter. May lag WDT_ENABLE1 by up to two LFCLK cycles.
    [8] WDT_ENABLE1 — Enable subcounter 1. May take up to 2 LFCLK cycles to take effect. 0: Counter is disabled (not clocked) 1: Counter is enabled (counting up)
    [3] WDT_RESET0 — Resets counter 0 back to 0000. Hardware will reset this bit after counter was reset. This will take up to one LFCLK cycle to take effect.
    [1] WDT_ENABLED0 ro — Indicates actual state of counter. May lag WDT_ENABLE0 by up to two LFCLK cycles.
    [0] WDT_ENABLE0 — Enable subcounter 0. May take up to 2 LFCLK cycles to take effect. 0: Counter is disabled (not clocked) 1: Counter is enabled (counting up)
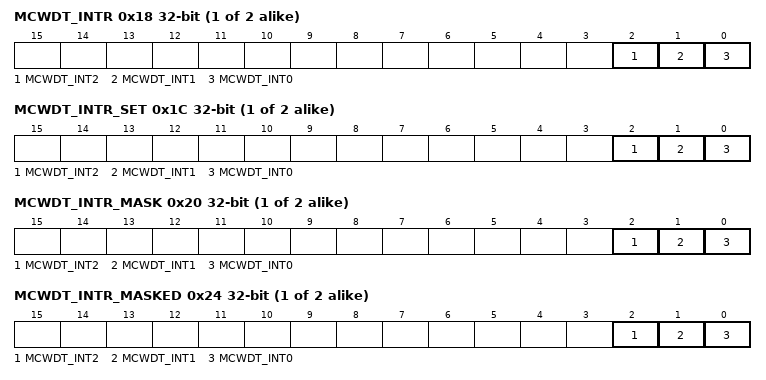
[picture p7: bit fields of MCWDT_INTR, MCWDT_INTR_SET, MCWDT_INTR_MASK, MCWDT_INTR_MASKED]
  0x18 MCWDT_INTR — Multi-Counter Watchdog Counter Interrupt Register
    [2] MCWDT_INT2 — MCWDT Interrupt Request for sub-counter 2. This bit is set by hardware as configured by this registers. This bit must be cleared by firmware. Clearing this bit also prevents Reset from happening when WDT_MODE2=3.
    [1] MCWDT_INT1 — MCWDT Interrupt Request for sub-counter 1. This bit is set by hardware as configured by this registers. This bit must be cleared by firmware. Clearing this bit also prevents Reset from happening when WDT_MODE1=3.
    [0] MCWDT_INT0 — MCWDT Interrupt Request for sub-counter 0. This bit is set by hardware as configured by this registers. This bit must be cleared by firmware. Clearing this bit also prevents Reset from happening when WDT_MODE0=3.
  0x1C MCWDT_INTR_SET — Multi-Counter Watchdog Counter Interrupt Set Register
    [2] MCWDT_INT2 — Set interrupt for MCWDT_INT2
    [1] MCWDT_INT1 — Set interrupt for MCWDT_INT1
    [0] MCWDT_INT0 — Set interrupt for MCWDT_INT0
  0x20 MCWDT_INTR_MASK — Multi-Counter Watchdog Counter Interrupt Mask Register
    [2] MCWDT_INT2 — Mask for sub-counter 2. This controls if the interrupt is forwarded to the CPU. 0: Interrupt is masked (not forwarded). 1: Interrupt is forwarded.
    [1] MCWDT_INT1 — Mask for sub-counter 1. This controls if the interrupt is forwarded to the CPU. 0: Interrupt is masked (not forwarded). 1: Interrupt is forwarded.
    [0] MCWDT_INT0 — Mask for sub-counter 0. This controls if the interrupt is forwarded to the CPU. 0: Interrupt is masked (not forwarded). 1: Interrupt is forwarded.
  0x24 MCWDT_INTR_MASKED ro — Multi-Counter Watchdog Counter Interrupt Masked Register
    [2] MCWDT_INT2 — Logical and of corresponding request and mask bits.
    [1] MCWDT_INT1 — Logical and of corresponding request and mask bits.
    [0] MCWDT_INT0 — Logical and of corresponding request and mask bits.
  0x28 MCWDT_LOCK — Multi-Counter Watchdog Counter Lock Register
    [31:30] MCWDT_LOCK — Prohibits writing control and configuration registers related to this MCWDT when not equal 0 (as specified in the other register descriptions). Requires at least two different writes to unlock. Note that this field is 2 bits to force multiple writes only. Each MCWDT has a separate local lock. LFCLK settings are locked by the global WDT_LOCK register, and this register has no effect on that.
      values as WDT_CTL.WDT_LOCK
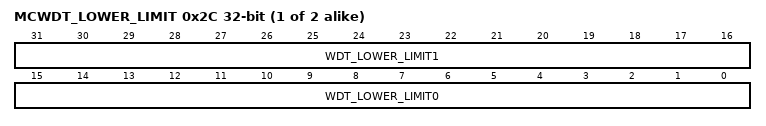
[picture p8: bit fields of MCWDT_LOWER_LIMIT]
  0x2C MCWDT_LOWER_LIMIT — Multi-Counter Watchdog Counter Lower Limit Register
    [31:16] WDT_LOWER_LIMIT1 — Lower limit for sub-counter 1 of this MCWDT
    [15:0] WDT_LOWER_LIMIT0 — Lower limit for sub-counter 0 of this MCWDT
